VERSION ""

NS_ :

BS_:

BU_: ECU

BO_ 2550136832 M0: 8 ECU
 SG_ S0_0 : 58|2@1- (1,0) [0|0] "u0" ECU

BO_ 257 M1: 8 ECU
 SG_ S1_0 : 3|40@1- (1,0) [0|0] "u0" ECU

BO_ 258 M2: 2 ECU
 SG_ S2_0 : 15|2@0+ (1,0) [0|0] "u0" ECU

BO_ 259 M3: 2 ECU
 SG_ S3_0 : 1|10@1+ (0.125,100.5) [0|0] "u0" ECU

BO_ 260 M4: 64 ECU
 SG_ S4_0 : 0|4@1+ (10,-40) [0|0] "u0" ECU

BO_ 2550136837 M5: 8 ECU
 SG_ S5_0 : 27|19@1- (0.01,-0.25) [0|0] "u0" ECU

BO_ 262 M6: 1 ECU
 SG_ S6_0 : 3|3@1+ (1,0) [0|0] "u0" ECU

BO_ 263 M7: 8 ECU
 SG_ S7_0 : 22|1@0+ (10,-40) [0|0] "u0" ECU

BO_ 264 M8: 4 ECU
 SG_ S8_0 : 19|7@0- (10,-0.25) [0|0] "u0" ECU

BO_ 265 M9: 1 ECU
 SG_ S9_0 : 6|7@0- (0.01,100.5) [0|0] "u0" ECU

BO_ 2550136842 M10: 4 ECU
 SG_ S10_0 : 7|32@0+ (1,0) [0|0] "u0" ECU

BO_ 267 M11: 8 ECU
 SG_ S11_0 : 7|64@0- (10,-40) [0|0] "u0" ECU

BO_ 268 M12: 2 ECU
 SG_ S12_0 : 0|16@1+ (1,0) [0|0] "u0" ECU

BO_ 269 M13: 8 ECU
 SG_ S13_0 : 29|26@1+ (0.01,-0.25) [0|0] "u0" ECU

BO_ 270 M14: 2 ECU
 SG_ S14_0 : 4|4@1+ (0.001,-0.25) [0|0] "u0" ECU

BO_ 2550136847 M15: 2 ECU
 SG_ S15_0 : 5|9@1+ (0.001,0) [0|0] "u0" ECU

BO_ 272 M16: 8 ECU
 SG_ S16_0 : 51|4@0+ (0.001,100.5) [0|0] "u0" ECU

BO_ 273 M17: 8 ECU
 SG_ S17_0 : 16|33@1+ (2,-40) [0|0] "u0" ECU

BO_ 274 M18: 8 ECU
 SG_ S18_0 : 6|43@1+ (2,-40) [0|0] "u0" ECU

BO_ 275 M19: 4 ECU
 SG_ S19_0 : 7|32@0+ (1,0) [0|0] "u0" ECU

BO_ 2550136852 M20: 4 ECU
 SG_ S20_0 : 8|24@1- (1,0) [0|0] "u0" ECU

BO_ 277 M21: 4 ECU
 SG_ S21_0 : 5|3@0- (0.001,0) [0|0] "u0" ECU

BO_ 278 M22: 16 ECU
 SG_ S22_0 : 73|47@0- (2,-40) [0|0] "u0" ECU

BO_ 279 M23: 4 ECU
 SG_ S23_0 : 0|1@1- (1,0) [0|0] "u0" ECU

BO_ 280 M24: 8 ECU
 SG_ S24_0 : 3|44@0- (0.125,100.5) [0|0] "u0" ECU

BO_ 2550136857 M25: 8 ECU
 SG_ S25_0 : 9|48@0- (2,-0.25) [0|0] "u0" ECU

BO_ 282 M26: 1 ECU
 SG_ S26_0 : 2|2@1+ (1,0) [0|0] "u0" ECU

BO_ 283 M27: 8 ECU
 SG_ S27_0 : 20|12@0- (1,0) [0|0] "u0" ECU

BO_ 284 M28: 2 ECU
 SG_ S28_0 : 4|10@1+ (10,-40) [0|0] "u0" ECU

BO_ 285 M29: 2 ECU
 SG_ S29_0 : 5|1@0- (1,0) [0|0] "u0" ECU

BO_ 2550136862 M30: 8 ECU
 SG_ S30_0 : 19|21@0+ (0.001,-40) [0|0] "u0" ECU

BO_ 287 M31: 8 ECU
 SG_ S31_0 : 7|62@0+ (0.001,-0.25) [0|0] "u0" ECU

BO_ 288 M32: 4 ECU
 SG_ S32_0 : 7|32@0+ (1,0) [0|0] "u0" ECU

BO_ 289 M33: 1 ECU
 SG_ S33_0 : 7|6@0+ (0.01,100.5) [0|0] "u0" ECU

BO_ 290 M34: 8 ECU
 SG_ S34_0 : 8|22@0+ (1,0) [0|0] "u0" ECU

BO_ 2550136867 M35: 16 ECU
 SG_ S35_0 : 42|46@0+ (0.125,-40) [0|0] "u0" ECU

BO_ 292 M36: 8 ECU
 SG_ S36_0 : 4|54@1- (1,0) [0|0] "u0" ECU

BO_ 293 M37: 8 ECU
 SG_ S37_0 : 6|62@0- (0.125,-40) [0|0] "u0" ECU

BO_ 294 M38: 64 ECU
 SG_ S38_0 : 293|7@0- (0.001,100.5) [0|0] "u0" ECU

BO_ 295 M39: 8 ECU
 SG_ S39_0 : 9|18@0+ (1,0) [0|0] "u0" ECU

BO_ 2550136872 M40: 1 ECU
 SG_ S40_0 : 7|8@0- (1,0) [0|0] "u0" ECU

BO_ 297 M41: 4 ECU
 SG_ S41_0 : 5|11@0+ (1,0) [0|0] "u0" ECU

BO_ 298 M42: 8 ECU
 SG_ S42_0 : 1|6@0+ (1,0) [0|0] "u0" ECU

BO_ 299 M43: 8 ECU
 SG_ S43_0 : 0|36@1- (1,0) [0|0] "u0" ECU

BO_ 300 M44: 8 ECU
 SG_ S44_0 : 26|36@1- (10,100.5) [0|0] "u0" ECU

BO_ 2550136877 M45: 8 ECU
 SG_ S45_0 : 5|48@1+ (1,0) [0|0] "u0" ECU

BO_ 302 M46: 16 ECU
 SG_ S46_0 : 68|27@1+ (1,0) [0|0] "u0" ECU

BO_ 303 M47: 64 ECU
 SG_ S47_0 : 199|39@1- (2,-0.25) [0|0] "u0" ECU

BO_ 304 M48: 16 ECU
 SG_ S48_0 : 10|44@0+ (1,0) [0|0] "u0" ECU

BO_ 305 M49: 8 ECU
 SG_ S49_0 : 0|25@1+ (0.01,0) [0|0] "u0" ECU

BO_ 2550136882 M50: 2 ECU
 SG_ S50_0 : 3|12@1- (1,0) [0|0] "u0" ECU

BO_ 307 M51: 8 ECU
 SG_ S51_0 : 1|6@1- (10,0) [0|0] "u0" ECU

BO_ 308 M52: 1 ECU
 SG_ S52_0 : 7|4@0+ (0.01,100.5) [0|0] "u0" ECU

BO_ 309 M53: 8 ECU
 SG_ S53_0 : 6|57@0+ (0.01,-0.25) [0|0] "u0" ECU

BO_ 310 M54: 2 ECU
 SG_ S54_0 : 0|1@1+ (0.001,100.5) [0|0] "u0" ECU

BO_ 2550136887 M55: 8 ECU
 SG_ S55_0 : 17|32@1+ (1,0) [0|0] "u0" ECU

BO_ 312 M56: 8 ECU
 SG_ S56_0 : 7|64@0+ (1,0) [0|0] "u0" ECU

BO_ 313 M57: 64 ECU
 SG_ S57_0 : 289|48@0+ (1,0) [0|0] "u0" ECU

BO_ 314 M58: 1 ECU
 SG_ S58_0 : 6|6@0+ (2,-0.25) [0|0] "u0" ECU

BO_ 315 M59: 1 ECU
 SG_ S59_0 : 2|1@1+ (1,0) [0|0] "u0" ECU

BO_ 2550136892 M60: 1 ECU
 SG_ S60_0 : 7|6@0- (1,0) [0|0] "u0" ECU

BO_ 317 M61: 64 ECU
 SG_ S61_0 : 373|42@0+ (2,100.5) [0|0] "u0" ECU

BO_ 318 M62: 1 ECU
 SG_ S62_0 : 0|2@1- (1,0) [0|0] "u0" ECU

BO_ 319 M63: 1 ECU
 SG_ S63_0 : 7|8@0+ (1,0) [0|0] "u0" ECU

BO_ 320 M64: 8 ECU
 SG_ S64_0 : 1|26@0- (2,-0.25) [0|0] "u0" ECU

BO_ 2550136897 M65: 8 ECU
 SG_ S65_0 : 12|5@1- (1,0) [0|0] "u0" ECU

BO_ 322 M66: 16 ECU
 SG_ S66_0 : 96|19@1+ (1,0) [0|0] "u0" ECU

BO_ 323 M67: 4 ECU
 SG_ S67_0 : 1|24@0- (1,0) [0|0] "u0" ECU

BO_ 324 M68: 2 ECU
 SG_ S68_0 : 5|2@0- (0.125,-0.25) [0|0] "u0" ECU

BO_ 325 M69: 64 ECU
 SG_ S69_0 : 277|25@1+ (1,0) [0|0] "u0" ECU

BO_ 2550136902 M70: 8 ECU
 SG_ S70_0 : 17|37@1- (1,0) [0|0] "u0" ECU

BO_ 327 M71: 8 ECU
 SG_ S71_0 : 4|40@0+ (2,-0.25) [0|0] "u0" ECU

BO_ 328 M72: 16 ECU
 SG_ S72_0 : 111|10@1+ (0.001,0) [0|0] "u0" ECU

BO_ 329 M73: 8 ECU
 SG_ S73_0 : 39|32@0+ (1,0) [0|0] "u0" ECU

BO_ 330 M74: 1 ECU
 SG_ S74_0 : 3|3@1+ (1,0) [0|0] "u0" ECU

BO_ 2550136907 M75: 8 ECU
 SG_ S75_0 : 15|32@0+ (1,0) [0|0] "u0" ECU

BO_ 332 M76: 8 ECU
 SG_ S76_0 : 9|50@0- (0.001,0) [0|0] "u0" ECU

BO_ 333 M77: 8 ECU
 SG_ S77_0 : 5|56@0+ (1,0) [0|0] "u0" ECU

BO_ 334 M78: 16 ECU
 SG_ S78_0 : 19|64@0+ (0.5,0) [0|0] "u0" ECU

BO_ 335 M79: 2 ECU
 SG_ S79_0 : 1|13@1- (0.125,-0.25) [0|0] "u0" ECU

BO_ 2550136912 M80: 16 ECU
 SG_ S80_0 : 31|58@1- (2,-40) [0|0] "u0" ECU

BO_ 337 M81: 4 ECU
 SG_ S81_0 : 31|1@1+ (0.01,0) [0|0] "u0" ECU

BO_ 338 M82: 16 ECU
 SG_ S82_0 : 34|40@0- (0.5,-0.25) [0|0] "u0" ECU

BO_ 339 M83: 1 ECU
 SG_ S83_0 : 0|3@1+ (0.001,0) [0|0] "u0" ECU

BO_ 340 M84: 1 ECU
 SG_ S84_0 : 7|8@0+ (1,0) [0|0] "u0" ECU

BO_ 2550136917 M85: 2 ECU
 SG_ S85_0 : 2|12@1- (0.01,-40) [0|0] "u0" ECU

BO_ 342 M86: 2 ECU
 SG_ S86_0 : 4|8@1+ (1,0) [0|0] "u0" ECU

BO_ 343 M87: 4 ECU
 SG_ S87_0 : 23|14@0- (1,0) [0|0] "u0" ECU

BO_ 344 M88: 8 ECU
 SG_ S88_0 : 3|51@0+ (1,0) [0|0] "u0" ECU

BO_ 345 M89: 64 ECU
 SG_ S89_0 : 290|39@0- (0.01,0) [0|0] "u0" ECU

BO_ 2550136922 M90: 1 ECU
 SG_ S90_0 : 1|5@1- (2,-0.25) [0|0] "u0" ECU

BO_ 347 M91: 16 ECU
 SG_ S91_0 : 26|64@0+ (1,0) [0|0] "u0" ECU

BO_ 348 M92: 4 ECU
 SG_ S92_0 : 7|24@0+ (0.125,100.5) [0|0] "u0" ECU

BO_ 349 M93: 8 ECU
 SG_ S93_0 : 13|39@0+ (0.125,-0.25) [0|0] "u0" ECU

BO_ 350 M94: 64 ECU
 SG_ S94_0 : 0|32@0+ (1,0) [0|0] "u0" ECU

BO_ 2550136927 M95: 8 ECU
 SG_ S95_0 : 5|52@1+ (0.125,-40) [0|0] "u0" ECU

BO_ 352 M96: 8 ECU
 SG_ S96_0 : 3|47@1- (10,-0.25) [0|0] "u0" ECU

BO_ 353 M97: 8 ECU
 SG_ S97_0 : 7|64@0+ (0.125,-0.25) [0|0] "u0" ECU

BO_ 354 M98: 4 ECU
 SG_ S98_0 : 5|22@0- (1,0) [0|0] "u0" ECU

BO_ 355 M99: 16 ECU
 SG_ S99_0 : 55|13@1+ (1,0) [0|0] "u0" ECU

BO_ 2550136932 M100: 8 ECU
 SG_ S100_0 : 7|59@0+ (10,100.5) [0|0] "u0" ECU

BO_ 357 M101: 8 ECU
 SG_ S101_0 : 23|32@0+ (1,0) [0|0] "u0" ECU

BO_ 358 M102: 2 ECU
 SG_ S102_0 : 5|10@1- (0.125,-0.25) [0|0] "u0" ECU

BO_ 359 M103: 8 ECU
 SG_ S103_0 : 11|11@1- (2,-0.25) [0|0] "u0" ECU

BO_ 360 M104: 8 ECU
 SG_ S104_0 : 18|41@1- (2,-40) [0|0] "u0" ECU

BO_ 2550136937 M105: 8 ECU
 SG_ S105_0 : 19|11@1- (10,-40) [0|0] "u0" ECU

BO_ 362 M106: 4 ECU
 SG_ S106_0 : 22|5@0- (10,-40) [0|0] "u0" ECU

BO_ 363 M107: 16 ECU
 SG_ S107_0 : 32|35@1- (1,0) [0|0] "u0" ECU

BO_ 364 M108: 16 ECU
 SG_ S108_0 : 69|55@0+ (10,-40) [0|0] "u0" ECU

BO_ 365 M109: 64 ECU
 SG_ S109_0 : 320|12@1- (0.125,-0.25) [0|0] "u0" ECU

BO_ 2550136942 M110: 8 ECU
 SG_ S110_0 : 45|6@1+ (0.5,-40) [0|0] "u0" ECU

BO_ 367 M111: 64 ECU
 SG_ S111_0 : 165|15@1- (10,-40) [0|0] "u0" ECU

BO_ 368 M112: 8 ECU
 SG_ S112_0 : 3|51@1- (1,0) [0|0] "u0" ECU

BO_ 369 M113: 8 ECU
 SG_ S113_0 : 3|60@0+ (1,0) [0|0] "u0" ECU

BO_ 370 M114: 8 ECU
 SG_ S114_0 : 5|30@1+ (0.125,100.5) [0|0] "u0" ECU

BO_ 2550136947 M115: 1 ECU
 SG_ S115_0 : 1|1@1- (0.01,-40) [0|0] "u0" ECU

BO_ 372 M116: 2 ECU
 SG_ S116_0 : 12|2@1- (0.125,100.5) [0|0] "u0" ECU

BO_ 374 M118: 8 ECU
 SG_ S118_0 : 50|9@1+ (0.001,-0.25) [0|0] "u0" ECU

BO_ 375 M119: 8 ECU
 SG_ S119_0 : 28|32@1+ (1,0) [0|0] "u0" ECU

BO_ 2550136952 M120: 4 ECU
 SG_ S120_0 : 0|31@1+ (1,0) [0|0] "u0" ECU

BO_ 377 M121: 8 ECU
 SG_ S121_0 : 4|15@0+ (10,-40) [0|0] "u0" ECU

BO_ 378 M122: 4 ECU
 SG_ S122_0 : 6|24@0- (0.01,-0.25) [0|0] "u0" ECU

BO_ 379 M123: 2 ECU
 SG_ S123_0 : 14|2@0+ (1,0) [0|0] "u0" ECU

BO_ 380 M124: 4 ECU
 SG_ S124_0 : 4|28@1+ (1,0) [0|0] "u0" ECU

BO_ 2550136957 M125: 2 ECU
 SG_ S125_0 : 6|11@0+ (2,0) [0|0] "u0" ECU

BO_ 382 M126: 1 ECU
 SG_ S126_0 : 4|5@0+ (1,0) [0|0] "u0" ECU

BO_ 383 M127: 64 ECU
 SG_ S127_0 : 219|64@0+ (1,0) [0|0] "u0" ECU

BO_ 384 M128: 16 ECU
 SG_ S128_0 : 38|32@1+ (1,0) [0|0] "u0" ECU

BO_ 385 M129: 4 ECU
 SG_ S129_0 : 18|7@1- (1,0) [0|0] "u0" ECU

BO_ 2550136962 M130: 8 ECU
 SG_ S130_0 : 9|32@1+ (1,0) [0|0] "u0" ECU

BO_ 387 M131: 16 ECU
 SG_ S131_0 : 78|55@0+ (10,-0.25) [0|0] "u0" ECU

BO_ 388 M132: 16 ECU
 SG_ S132_0 : 20|57@1- (1,0) [0|0] "u0" ECU

BO_ 389 M133: 1 ECU
 SG_ S133_0 : 7|1@1+ (2,-0.25) [0|0] "u0" ECU

BO_ 390 M134: 8 ECU
 SG_ S134_0 : 7|23@1+ (1,0) [0|0] "u0" ECU

BO_ 2550136967 M135: 16 ECU
 SG_ S135_0 : 45|40@0- (1,0) [0|0] "u0" ECU

BO_ 392 M136: 8 ECU
 SG_ S136_0 : 44|15@1+ (0.001,-0.25) [0|0] "u0" ECU

BO_ 393 M137: 64 ECU
 SG_ S137_0 : 5|52@1+ (0.001,0) [0|0] "u0" ECU

BO_ 394 M138: 64 ECU
 SG_ S138_0 : 461|15@1- (1,0) [0|0] "u0" ECU

BO_ 395 M139: 8 ECU
 SG_ S139_0 : 29|32@1- (1,0) [0|0] "u0" ECU

BO_ 2550136972 M140: 8 ECU
 SG_ S140_0 : 1|61@1- (1,0) [0|0] "u0" ECU

BO_ 397 M141: 8 ECU
 SG_ S141_0 : 5|26@1- (1,0) [0|0] "u0" ECU

BO_ 398 M142: 1 ECU
 SG_ S142_0 : 0|1@0+ (2,100.5) [0|0] "u0" ECU

BO_ 399 M143: 8 ECU
 SG_ S143_0 : 37|13@0+ (0.125,-40) [0|0] "u0" ECU

BO_ 400 M144: 8 ECU
 SG_ S144_0 : 13|16@1+ (0.001,-40) [0|0] "u0" ECU

BO_ 2550136977 M145: 4 ECU
 SG_ S145_0 : 0|26@1- (0.5,0) [0|0] "u0" ECU

BO_ 402 M146: 16 ECU
 SG_ S146_0 : 102|23@1+ (1,0) [0|0] "u0" ECU

BO_ 403 M147: 8 ECU
 SG_ S147_0 : 5|55@1- (1,0) [0|0] "u0" ECU

BO_ 404 M148: 64 ECU
 SG_ S148_0 : 479|35@0+ (1,0) [0|0] "u0" ECU

BO_ 405 M149: 16 ECU
 SG_ S149_0 : 22|38@0+ (1,0) [0|0] "u0" ECU

BO_ 2550136982 M150: 4 ECU
 SG_ S150_0 : 1|24@1- (0.125,-0.25) [0|0] "u0" ECU

BO_ 407 M151: 8 ECU
 SG_ S151_0 : 25|15@1+ (1,0) [0|0] "u0" ECU

BO_ 408 M152: 1 ECU
 SG_ S152_0 : 4|2@0+ (1,0) [0|0] "u0" ECU

BO_ 409 M153: 4 ECU
 SG_ S153_0 : 8|18@1+ (10,0) [0|0] "u0" ECU

BO_ 410 M154: 1 ECU
 SG_ S154_0 : 7|8@0- (0.125,-40) [0|0] "u0" ECU

BO_ 2550136987 M155: 1 ECU
 SG_ S155_0 : 1|1@0- (1,0) [0|0] "u0" ECU

BO_ 412 M156: 2 ECU
 SG_ S156_0 : 0|10@1- (1,0) [0|0] "u0" ECU

BO_ 413 M157: 1 ECU
 SG_ S157_0 : 0|7@1+ (1,0) [0|0] "u0" ECU

BO_ 414 M158: 8 ECU
 SG_ S158_0 : 12|46@1+ (1,0) [0|0] "u0" ECU

BO_ 415 M159: 2 ECU
 SG_ S159_0 : 7|3@0- (1,0) [0|0] "u0" ECU

BO_ 2550136992 M160: 64 ECU
 SG_ S160_0 : 53|51@1- (0.125,-0.25) [0|0] "u0" ECU

BO_ 417 M161: 64 ECU
 SG_ S161_0 : 294|20@1+ (0.01,-40) [0|0] "u0" ECU

BO_ 418 M162: 2 ECU
 SG_ S162_0 : 7|6@1- (1,0) [0|0] "u0" ECU

BO_ 419 M163: 8 ECU
 SG_ S163_0 : 9|49@0+ (1,0) [0|0] "u0" ECU

BO_ 420 M164: 4 ECU
 SG_ S164_0 : 19|6@1- (1,0) [0|0] "u0" ECU

BO_ 2550136997 M165: 8 ECU
 SG_ S165_0 : 5|43@0- (10,-0.25) [0|0] "u0" ECU

BO_ 422 M166: 4 ECU
 SG_ S166_0 : 0|14@1- (0.125,0) [0|0] "u0" ECU

BO_ 423 M167: 1 ECU
 SG_ S167_0 : 0|7@1- (1,0) [0|0] "u0" ECU

BO_ 424 M168: 2 ECU
 SG_ S168_0 : 4|7@0- (0.125,0) [0|0] "u0" ECU

BO_ 425 M169: 8 ECU
 SG_ S169_0 : 35|8@0- (1,0) [0|0] "u0" ECU

BO_ 2550137002 M170: 4 ECU
 SG_ S170_0 : 6|25@1+ (1,0) [0|0] "u0" ECU

BO_ 427 M171: 8 ECU
 SG_ S171_0 : 16|48@1+ (1,0) [0|0] "u0" ECU

BO_ 428 M172: 8 ECU
 SG_ S172_0 : 3|55@0+ (0.5,0) [0|0] "u0" ECU

BO_ 429 M173: 2 ECU
 SG_ S173_0 : 3|10@1+ (0.5,-0.25) [0|0] "u0" ECU

BO_ 430 M174: 8 ECU
 SG_ S174_0 : 56|8@1+ (0.001,-40) [0|0] "u0" ECU

BO_ 2550137007 M175: 64 ECU
 SG_ S175_0 : 305|9@1- (1,0) [0|0] "u0" ECU

BO_ 432 M176: 1 ECU
 SG_ S176_0 : 2|6@1+ (0.125,-40) [0|0] "u0" ECU

BO_ 433 M177: 8 ECU
 SG_ S177_0 : 7|64@0+ (1,0) [0|0] "u0" ECU

BO_ 434 M178: 8 ECU
 SG_ S178_0 : 2|61@1- (1,0) [0|0] "u0" ECU

BO_ 435 M179: 16 ECU
 SG_ S179_0 : 32|41@1+ (0.125,-40) [0|0] "u0" ECU

BO_ 2550137012 M180: 1 ECU
 SG_ S180_0 : 0|8@1+ (0.001,-0.25) [0|0] "u0" ECU

BO_ 437 M181: 8 ECU
 SG_ S181_0 : 35|24@0- (0.01,0) [0|0] "u0" ECU

BO_ 438 M182: 8 ECU
 SG_ S182_0 : 5|43@1+ (0.125,0) [0|0] "u0" ECU

BO_ 439 M183: 8 ECU
 SG_ S183_0 : 7|47@1- (0.001,-0.25) [0|0] "u0" ECU

BO_ 440 M184: 8 ECU
 SG_ S184_0 : 0|59@1- (1,0) [0|0] "u0" ECU

BO_ 2550137017 M185: 16 ECU
 SG_ S185_0 : 79|28@1+ (1,0) [0|0] "u0" ECU

BO_ 442 M186: 8 ECU
 SG_ S186_0 : 0|64@1+ (1,0) [0|0] "u0" ECU

BO_ 443 M187: 2 ECU
 SG_ S187_0 : 1|8@1+ (1,0) [0|0] "u0" ECU

BO_ 444 M188: 16 ECU
 SG_ S188_0 : 37|62@1- (1,0) [0|0] "u0" ECU

BO_ 445 M189: 1 ECU
 SG_ S189_0 : 6|1@1- (1,0) [0|0] "u0" ECU

BO_ 2550137022 M190: 8 ECU
 SG_ S190_0 : 25|33@1+ (2,-0.25) [0|0] "u0" ECU

BO_ 447 M191: 8 ECU
 SG_ S191_0 : 0|60@1- (1,0) [0|0] "u0" ECU

BO_ 448 M192: 1 ECU
 SG_ S192_0 : 2|2@1+ (1,0) [0|0] "u0" ECU

BO_ 449 M193: 2 ECU
 SG_ S193_0 : 0|8@0- (0.01,0) [0|0] "u0" ECU

BO_ 450 M194: 8 ECU
 SG_ S194_0 : 26|7@1+ (1,0) [0|0] "u0" ECU

BO_ 2550137027 M195: 16 ECU
 SG_ S195_0 : 20|19@0+ (1,0) [0|0] "u0" ECU

BO_ 452 M196: 8 ECU
 SG_ S196_0 : 41|17@1+ (1,0) [0|0] "u0" ECU

BO_ 453 M197: 1 ECU
 SG_ S197_0 : 3|4@0+ (1,0) [0|0] "u0" ECU

BO_ 454 M198: 16 ECU
 SG_ S198_0 : 75|20@1+ (1,0) [0|0] "u0" ECU

BO_ 455 M199: 1 ECU
 SG_ S199_0 : 3|2@0- (0.5,-0.25) [0|0] "u0" ECU

BO_ 2550137032 M200: 16 ECU
 SG_ S200_0 : 90|35@1- (0.125,-40) [0|0] "u0" ECU

BO_ 457 M201: 4 ECU
 SG_ S201_0 : 7|32@0+ (0.5,0) [0|0] "u0" ECU

BO_ 458 M202: 8 ECU
 SG_ S202_0 : 0|64@1+ (1,0) [0|0] "u0" ECU

BO_ 459 M203: 2 ECU
 SG_ S203_0 : 4|11@1+ (10,0) [0|0] "u0" ECU

BO_ 460 M204: 8 ECU
 SG_ S204_0 : 6|58@1+ (2,100.5) [0|0] "u0" ECU

BO_ 2550137037 M205: 16 ECU
 SG_ S205_0 : 25|43@1- (1,0) [0|0] "u0" ECU

BO_ 462 M206: 1 ECU
 SG_ S206_0 : 0|6@1+ (1,0) [0|0] "u0" ECU

BO_ 463 M207: 64 ECU
 SG_ S207_0 : 431|34@0- (1,0) [0|0] "u0" ECU

BO_ 464 M208: 8 ECU
 SG_ S208_0 : 3|9@0- (0.125,-0.25) [0|0] "u0" ECU

BO_ 465 M209: 1 ECU
 SG_ S209_0 : 4|4@1+ (2,-40) [0|0] "u0" ECU

BO_ 2550137042 M210: 2 ECU
 SG_ S210_0 : 13|2@0- (1,0) [0|0] "u0" ECU

BO_ 467 M211: 8 ECU
 SG_ S211_0 : 13|32@0+ (1,0) [0|0] "u0" ECU

BO_ 468 M212: 8 ECU
 SG_ S212_0 : 8|12@1+ (0.001,0) [0|0] "u0" ECU

BO_ 469 M213: 4 ECU
 SG_ S213_0 : 0|19@1+ (2,100.5) [0|0] "u0" ECU

BO_ 470 M214: 8 ECU
 SG_ S214_0 : 9|43@1+ (0.5,100.5) [0|0] "u0" ECU

BO_ 2550137047 M215: 16 ECU
 SG_ S215_0 : 53|17@0+ (1,0) [0|0] "u0" ECU

BO_ 473 M217: 8 ECU
 SG_ S217_0 : 34|20@0- (0.001,0) [0|0] "u0" ECU

BO_ 474 M218: 4 ECU
 SG_ S218_0 : 9|11@0- (1,0) [0|0] "u0" ECU

BO_ 475 M219: 64 ECU
 SG_ S219_0 : 241|47@0- (1,0) [0|0] "u0" ECU

BO_ 2550137052 M220: 2 ECU
 SG_ S220_0 : 7|16@0- (0.5,100.5) [0|0] "u0" ECU

BO_ 477 M221: 1 ECU
 SG_ S221_0 : 2|5@1- (0.01,100.5) [0|0] "u0" ECU

BO_ 478 M222: 2 ECU
 SG_ S222_0 : 6|3@0- (0.001,100.5) [0|0] "u0" ECU

BO_ 479 M223: 1 ECU
 SG_ S223_0 : 4|1@1+ (1,0) [0|0] "u0" ECU

BO_ 480 M224: 4 ECU
 SG_ S224_0 : 14|21@0+ (1,0) [0|0] "u0" ECU

BO_ 2550137057 M225: 1 ECU
 SG_ S225_0 : 4|2@1+ (1,0) [0|0] "u0" ECU

BO_ 482 M226: 64 ECU
 SG_ S226_0 : 84|19@0+ (0.125,0) [0|0] "u0" ECU

BO_ 483 M227: 64 ECU
 SG_ S227_0 : 286|64@1+ (1,0) [0|0] "u0" ECU

BO_ 484 M228: 64 ECU
 SG_ S228_0 : 136|13@0- (1,0) [0|0] "u0" ECU

BO_ 485 M229: 1 ECU
 SG_ S229_0 : 2|5@1+ (1,0) [0|0] "u0" ECU

BO_ 2550137062 M230: 8 ECU
 SG_ S230_0 : 12|44@0+ (1,0) [0|0] "u0" ECU

BO_ 487 M231: 1 ECU
 SG_ S231_0 : 7|1@0- (0.5,-40) [0|0] "u0" ECU

BO_ 488 M232: 4 ECU
 SG_ S232_0 : 3|28@1- (1,0) [0|0] "u0" ECU

BO_ 489 M233: 16 ECU
 SG_ S233_0 : 68|23@0- (0.5,0) [0|0] "u0" ECU

BO_ 490 M234: 8 ECU
 SG_ S234_0 : 19|16@0+ (0.01,-0.25) [0|0] "u0" ECU

BO_ 2550137067 M235: 8 ECU
 SG_ S235_0 : 5|36@0+ (0.01,-0.25) [0|0] "u0" ECU

BO_ 492 M236: 16 ECU
 SG_ S236_0 : 28|64@1+ (1,0) [0|0] "u0" ECU

BO_ 493 M237: 8 ECU
 SG_ S237_0 : 6|2@1+ (1,0) [0|0] "u0" ECU

BO_ 494 M238: 8 ECU
 SG_ S238_0 : 7|64@0+ (10,-0.25) [0|0] "u0" ECU

BO_ 495 M239: 8 ECU
 SG_ S239_0 : 7|18@0- (2,-0.25) [0|0] "u0" ECU

BO_ 2550137072 M240: 8 ECU
 SG_ S240_0 : 7|64@0+ (1,0) [0|0] "u0" ECU

BO_ 497 M241: 64 ECU
 SG_ S241_0 : 76|5@1+ (1,0) [0|0] "u0" ECU

BO_ 498 M242: 16 ECU
 SG_ S242_0 : 13|26@1+ (0.5,-0.25) [0|0] "u0" ECU

BO_ 499 M243: 8 ECU
 SG_ S243_0 : 10|37@0- (1,0) [0|0] "u0" ECU

BO_ 500 M244: 8 ECU
 SG_ S244_0 : 4|61@0- (1,0) [0|0] "u0" ECU

BO_ 2550137077 M245: 4 ECU
 SG_ S245_0 : 13|10@0+ (1,0) [0|0] "u0" ECU

BO_ 502 M246: 2 ECU
 SG_ S246_0 : 3|7@1- (0.001,-40) [0|0] "u0" ECU

BO_ 503 M247: 16 ECU
 SG_ S247_0 : 49|62@1+ (2,0) [0|0] "u0" ECU

BO_ 504 M248: 64 ECU
 SG_ S248_0 : 179|20@0- (1,0) [0|0] "u0" ECU

BO_ 505 M249: 8 ECU
 SG_ S249_0 : 19|26@1- (2,0) [0|0] "u0" ECU

BO_ 2550137082 M250: 8 ECU
 SG_ S250_0 : 22|30@0- (0.01,-40) [0|0] "u0" ECU

BO_ 507 M251: 16 ECU
 SG_ S251_0 : 16|60@0- (0.5,-0.25) [0|0] "u0" ECU

BO_ 508 M252: 8 ECU
 SG_ S252_0 : 0|54@1- (10,-0.25) [0|0] "u0" ECU

BO_ 509 M253: 8 ECU
 SG_ S253_0 : 24|2@1+ (1,0) [0|0] "u0" ECU

BO_ 510 M254: 8 ECU
 SG_ S254_0 : 8|32@1+ (1,0) [0|0] "u0" ECU

BO_ 2550137087 M255: 64 ECU
 SG_ S255_0 : 281|18@1- (0.01,100.5) [0|0] "u0" ECU

BO_ 512 M256: 16 ECU
 SG_ S256_0 : 56|9@1- (1,0) [0|0] "u0" ECU

BO_ 513 M257: 16 ECU
 SG_ S257_0 : 48|58@1- (1,0) [0|0] "u0" ECU

BO_ 514 M258: 2 ECU
 SG_ S258_0 : 5|13@0- (10,0) [0|0] "u0" ECU

BO_ 515 M259: 8 ECU
 SG_ S259_0 : 14|10@1- (1,0) [0|0] "u0" ECU

BO_ 2550137092 M260: 4 ECU
 SG_ S260_0 : 1|26@1+ (1,0) [0|0] "u0" ECU

BO_ 517 M261: 8 ECU
 SG_ S261_0 : 5|55@0+ (1,0) [0|0] "u0" ECU

BO_ 518 M262: 4 ECU
 SG_ S262_0 : 11|18@0+ (1,0) [0|0] "u0" ECU

BO_ 519 M263: 4 ECU
 SG_ S263_0 : 7|32@0+ (1,0) [0|0] "u0" ECU

BO_ 520 M264: 4 ECU
 SG_ S264_0 : 7|25@0- (1,0) [0|0] "u0" ECU

BO_ 2550137097 M265: 2 ECU
 SG_ S265_0 : 1|7@1+ (0.5,100.5) [0|0] "u0" ECU

BO_ 522 M266: 2 ECU
 SG_ S266_0 : 0|5@1+ (0.001,100.5) [0|0] "u0" ECU

BO_ 523 M267: 4 ECU
 SG_ S267_0 : 1|4@0- (1,0) [0|0] "u0" ECU

BO_ 524 M268: 8 ECU
 SG_ S268_0 : 14|41@1- (2,-0.25) [0|0] "u0" ECU

BO_ 525 M269: 8 ECU
 SG_ S269_0 : 35|17@0+ (0.5,-0.25) [0|0] "u0" ECU

BO_ 2550137102 M270: 16 ECU
 SG_ S270_0 : 59|54@1+ (0.5,-40) [0|0] "u0" ECU

BO_ 527 M271: 1 ECU
 SG_ S271_0 : 4|1@0- (1,0) [0|0] "u0" ECU

BO_ 528 M272: 8 ECU
 SG_ S272_0 : 0|56@0+ (1,0) [0|0] "u0" ECU

BO_ 529 M273: 16 ECU
 SG_ S273_0 : 103|26@0- (0.01,-40) [0|0] "u0" ECU

BO_ 530 M274: 2 ECU
 SG_ S274_0 : 0|2@1- (1,0) [0|0] "u0" ECU

BO_ 2550137107 M275: 2 ECU
 SG_ S275_0 : 2|5@1+ (1,0) [0|0] "u0" ECU

BO_ 532 M276: 4 ECU
 SG_ S276_0 : 7|32@0+ (10,-0.25) [0|0] "u0" ECU

BO_ 533 M277: 2 ECU
 SG_ S277_0 : 0|14@1- (2,100.5) [0|0] "u0" ECU

BO_ 534 M278: 64 ECU
 SG_ S278_0 : 346|39@1- (1,0) [0|0] "u0" ECU

BO_ 535 M279: 16 ECU
 SG_ S279_0 : 68|57@0+ (0.5,0) [0|0] "u0" ECU

BO_ 2550137112 M280: 8 ECU
 SG_ S280_0 : 4|7@0- (1,0) [0|0] "u0" ECU

BO_ 537 M281: 8 ECU
 SG_ S281_0 : 26|19@0- (0.001,-0.25) [0|0] "u0" ECU

BO_ 538 M282: 16 ECU
 SG_ S282_0 : 22|19@0+ (1,0) [0|0] "u0" ECU

BO_ 539 M283: 8 ECU
 SG_ S283_0 : 14|36@1+ (0.5,-40) [0|0] "u0" ECU

BO_ 540 M284: 16 ECU
 SG_ S284_0 : 22|54@0- (0.125,100.5) [0|0] "u0" ECU

BO_ 2550137117 M285: 4 ECU
 SG_ S285_0 : 0|18@0+ (0.125,100.5) [0|0] "u0" ECU

BO_ 542 M286: 16 ECU
 SG_ S286_0 : 56|55@1- (2,-40) [0|0] "u0" ECU

BO_ 543 M287: 8 ECU
 SG_ S287_0 : 37|16@0- (0.001,-0.25) [0|0] "u0" ECU

BO_ 544 M288: 8 ECU
 SG_ S288_0 : 27|23@1+ (0.001,-40) [0|0] "u0" ECU

BO_ 545 M289: 8 ECU
 SG_ S289_0 : 35|21@1+ (0.01,-40) [0|0] "u0" ECU

BO_ 2550137122 M290: 8 ECU
 SG_ S290_0 : 7|64@0+ (1,0) [0|0] "u0" ECU

BO_ 547 M291: 8 ECU
 SG_ S291_0 : 21|27@1+ (1,0) [0|0] "u0" ECU

BO_ 548 M292: 8 ECU
 SG_ S292_0 : 30|32@1+ (1,0) [0|0] "u0" ECU

BO_ 549 M293: 4 ECU
 SG_ S293_0 : 1|30@1+ (0.01,-0.25) [0|0] "u0" ECU

BO_ 550 M294: 16 ECU
 SG_ S294_0 : 57|20@0- (0.5,100.5) [0|0] "u0" ECU

BO_ 2550137127 M295: 64 ECU
 SG_ S295_0 : 403|20@0+ (0.01,0) [0|0] "u0" ECU

BO_ 552 M296: 16 ECU
 SG_ S296_0 : 111|8@1+ (0.001,100.5) [0|0] "u0" ECU

BO_ 553 M297: 2 ECU
 SG_ S297_0 : 0|3@0- (1,0) [0|0] "u0" ECU

BO_ 554 M298: 16 ECU
 SG_ S298_0 : 32|17@1- (1,0) [0|0] "u0" ECU

BO_ 555 M299: 4 ECU
 SG_ S299_0 : 29|4@0- (0.5,-40) [0|0] "u0" ECU

BO_ 2550137132 M300: 2 ECU
 SG_ S300_0 : 0|13@1- (0.125,-40) [0|0] "u0" ECU

BO_ 557 M301: 8 ECU
 SG_ S301_0 : 46|9@1+ (0.001,100.5) [0|0] "u0" ECU

BO_ 558 M302: 8 ECU
 SG_ S302_0 : 2|44@1- (1,0) [0|0] "u0" ECU

BO_ 559 M303: 1 ECU
 SG_ S303_0 : 6|5@0+ (2,0) [0|0] "u0" ECU

BO_ 560 M304: 4 ECU
 SG_ S304_0 : 2|9@1- (1,0) [0|0] "u0" ECU

BO_ 2550137137 M305: 4 ECU
 SG_ S305_0 : 7|32@0+ (1,0) [0|0] "u0" ECU

BO_ 562 M306: 1 ECU
 SG_ S306_0 : 5|5@0+ (10,-0.25) [0|0] "u0" ECU

BO_ 563 M307: 1 ECU
 SG_ S307_0 : 1|5@1+ (10,0) [0|0] "u0" ECU

BO_ 564 M308: 1 ECU
 SG_ S308_0 : 6|6@0+ (1,0) [0|0] "u0" ECU

BO_ 565 M309: 8 ECU
 SG_ S309_0 : 44|16@0+ (2,-0.25) [0|0] "u0" ECU

BO_ 2550137142 M310: 2 ECU
 SG_ S310_0 : 7|13@0+ (2,100.5) [0|0] "u0" ECU

BO_ 567 M311: 1 ECU
 SG_ S311_0 : 6|2@1- (2,0) [0|0] "u0" ECU

BO_ 568 M312: 8 ECU
 SG_ S312_0 : 7|57@1- (0.01,-40) [0|0] "u0" ECU

BO_ 569 M313: 16 ECU
 SG_ S313_0 : 67|28@0+ (1,0) [0|0] "u0" ECU

BO_ 570 M314: 8 ECU
 SG_ S314_0 : 5|49@0+ (1,0) [0|0] "u0" ECU

BO_ 2550137147 M315: 8 ECU
 SG_ S315_0 : 9|46@0+ (0.125,-0.25) [0|0] "u0" ECU

BO_ 572 M316: 8 ECU
 SG_ S316_0 : 1|15@1- (1,0) [0|0] "u0" ECU

BO_ 573 M317: 16 ECU
 SG_ S317_0 : 34|26@1- (1,0) [0|0] "u0" ECU

BO_ 574 M318: 8 ECU
 SG_ S318_0 : 6|24@0- (1,0) [0|0] "u0" ECU

BO_ 575 M319: 8 ECU
 SG_ S319_0 : 14|55@0- (1,0) [0|0] "u0" ECU

BO_ 2550137152 M320: 8 ECU
 SG_ S320_0 : 0|26@0- (1,0) [0|0] "u0" ECU

BO_ 577 M321: 1 ECU
 SG_ S321_0 : 7|5@0+ (1,0) [0|0] "u0" ECU

BO_ 578 M322: 2 ECU
 SG_ S322_0 : 6|15@0- (1,0) [0|0] "u0" ECU

BO_ 579 M323: 1 ECU
 SG_ S323_0 : 5|4@0- (1,0) [0|0] "u0" ECU

BO_ 580 M324: 8 ECU
 SG_ S324_0 : 7|48@0- (0.001,-0.25) [0|0] "u0" ECU

BO_ 2550137157 M325: 4 ECU
 SG_ S325_0 : 0|3@1+ (1,0) [0|0] "u0" ECU

BO_ 582 M326: 64 ECU
 SG_ S326_0 : 308|8@0- (1,0) [0|0] "u0" ECU

BO_ 583 M327: 8 ECU
 SG_ S327_0 : 7|61@0+ (0.125,100.5) [0|0] "u0" ECU

BO_ 584 M328: 8 ECU
 SG_ S328_0 : 19|44@1- (2,0) [0|0] "u0" ECU

BO_ 585 M329: 64 ECU
 SG_ S329_0 : 110|30@1+ (0.01,-0.25) [0|0] "u0" ECU

BO_ 2550137162 M330: 64 ECU
 SG_ S330_0 : 331|51@1+ (0.5,100.5) [0|0] "u0" ECU

BO_ 587 M331: 8 ECU
 SG_ S331_0 : 4|58@0- (1,0) [0|0] "u0" ECU

BO_ 588 M332: 8 ECU
 SG_ S332_0 : 2|22@1+ (10,-40) [0|0] "u0" ECU

BO_ 589 M333: 4 ECU
 SG_ S333_0 : 2|6@1+ (0.5,-40) [0|0] "u0" ECU

BO_ 590 M334: 64 ECU
 SG_ S334_0 : 148|17@1- (0.001,-0.25) [0|0] "u0" ECU

BO_ 2550137167 M335: 4 ECU
 SG_ S335_0 : 2|28@1+ (10,-40) [0|0] "u0" ECU

BO_ 592 M336: 4 ECU
 SG_ S336_0 : 5|29@0- (1,0) [0|0] "u0" ECU

BO_ 593 M337: 16 ECU
 SG_ S337_0 : 66|52@0- (10,-40) [0|0] "u0" ECU

BO_ 594 M338: 16 ECU
 SG_ S338_0 : 37|29@1+ (1,0) [0|0] "u0" ECU

BO_ 595 M339: 8 ECU
 SG_ S339_0 : 18|36@0+ (0.5,-0.25) [0|0] "u0" ECU

BO_ 2550137172 M340: 8 ECU
 SG_ S340_0 : 11|49@1- (1,0) [0|0] "u0" ECU

BO_ 597 M341: 8 ECU
 SG_ S341_0 : 25|27@1+ (0.5,0) [0|0] "u0" ECU

BO_ 598 M342: 8 ECU
 SG_ S342_0 : 0|52@1+ (1,0) [0|0] "u0" ECU

BO_ 599 M343: 64 ECU
 SG_ S343_0 : 473|18@0- (0.01,100.5) [0|0] "u0" ECU

BO_ 600 M344: 1 ECU
 SG_ S344_0 : 1|5@1+ (0.001,100.5) [0|0] "u0" ECU

BO_ 2550137177 M345: 8 ECU
 SG_ S345_0 : 31|8@0+ (1,0) [0|0] "u0" ECU

BO_ 602 M346: 64 ECU
 SG_ S346_0 : 246|64@0- (0.5,100.5) [0|0] "u0" ECU

BO_ 603 M347: 4 ECU
 SG_ S347_0 : 18|10@1- (1,0) [0|0] "u0" ECU

BO_ 604 M348: 8 ECU
 SG_ S348_0 : 7|39@1+ (0.001,100.5) [0|0] "u0" ECU

BO_ 605 M349: 8 ECU
 SG_ S349_0 : 26|29@0+ (1,0) [0|0] "u0" ECU

BO_ 2550137182 M350: 4 ECU
 SG_ S350_0 : 13|8@1- (0.125,-0.25) [0|0] "u0" ECU

BO_ 607 M351: 8 ECU
 SG_ S351_0 : 12|18@1+ (1,0) [0|0] "u0" ECU

BO_ 608 M352: 2 ECU
 SG_ S352_0 : 7|16@0- (1,0) [0|0] "u0" ECU

BO_ 609 M353: 64 ECU
 SG_ S353_0 : 242|29@1+ (1,0) [0|0] "u0" ECU

BO_ 610 M354: 64 ECU
 SG_ S354_0 : 119|43@0+ (0.001,0) [0|0] "u0" ECU

BO_ 2550137187 M355: 8 ECU
 SG_ S355_0 : 27|27@1- (0.01,-0.25) [0|0] "u0" ECU

BO_ 612 M356: 16 ECU
 SG_ S356_0 : 40|64@0+ (0.125,100.5) [0|0] "u0" ECU

BO_ 613 M357: 1 ECU
 SG_ S357_0 : 6|1@0- (1,0) [0|0] "u0" ECU

BO_ 614 M358: 8 ECU
 SG_ S358_0 : 38|12@1+ (1,0) [0|0] "u0" ECU

BO_ 615 M359: 64 ECU
 SG_ S359_0 : 243|8@1+ (0.5,100.5) [0|0] "u0" ECU

BO_ 2550137192 M360: 1 ECU
 SG_ S360_0 : 5|3@1- (0.125,0) [0|0] "u0" ECU

BO_ 617 M361: 1 ECU
 SG_ S361_0 : 4|4@1+ (0.5,0) [0|0] "u0" ECU

BO_ 618 M362: 8 ECU
 SG_ S362_0 : 7|64@0- (1,0) [0|0] "u0" ECU

BO_ 619 M363: 16 ECU
 SG_ S363_0 : 6|5@0- (1,0) [0|0] "u0" ECU

BO_ 620 M364: 16 ECU
 SG_ S364_0 : 12|23@0+ (0.01,0) [0|0] "u0" ECU

BO_ 2550137197 M365: 8 ECU
 SG_ S365_0 : 2|39@1- (10,-40) [0|0] "u0" ECU

BO_ 622 M366: 64 ECU
 SG_ S366_0 : 336|5@1+ (10,-40) [0|0] "u0" ECU

BO_ 623 M367: 8 ECU
 SG_ S367_0 : 9|4@0+ (2,-0.25) [0|0] "u0" ECU

BO_ 624 M368: 64 ECU
 SG_ S368_0 : 194|28@0+ (1,0) [0|0] "u0" ECU

BO_ 625 M369: 4 ECU
 SG_ S369_0 : 17|3@0+ (1,0) [0|0] "u0" ECU

BO_ 2550137202 M370: 1 ECU
 SG_ S370_0 : 6|1@1+ (0.5,0) [0|0] "u0" ECU

BO_ 627 M371: 1 ECU
 SG_ S371_0 : 0|3@1+ (1,0) [0|0] "u0" ECU

BO_ 628 M372: 8 ECU
 SG_ S372_0 : 21|40@0- (10,-40) [0|0] "u0" ECU

BO_ 629 M373: 16 ECU
 SG_ S373_0 : 47|29@1+ (0.01,-40) [0|0] "u0" ECU

BO_ 630 M374: 8 ECU
 SG_ S374_0 : 1|36@1- (0.001,100.5) [0|0] "u0" ECU

BO_ 2550137207 M375: 16 ECU
 SG_ S375_0 : 79|48@0- (2,100.5) [0|0] "u0" ECU

BO_ 632 M376: 1 ECU
 SG_ S376_0 : 0|5@1+ (0.5,100.5) [0|0] "u0" ECU

BO_ 633 M377: 8 ECU
 SG_ S377_0 : 14|21@0- (0.001,0) [0|0] "u0" ECU

BO_ 634 M378: 8 ECU
 SG_ S378_0 : 2|19@0- (0.5,-0.25) [0|0] "u0" ECU

BO_ 635 M379: 8 ECU
 SG_ S379_0 : 16|32@0+ (1,0) [0|0] "u0" ECU

BO_ 2550137212 M380: 2 ECU
 SG_ S380_0 : 0|9@0+ (1,0) [0|0] "u0" ECU

BO_ 637 M381: 64 ECU
 SG_ S381_0 : 390|32@0- (1,0) [0|0] "u0" ECU

BO_ 638 M382: 64 ECU
 SG_ S382_0 : 23|16@0- (1,0) [0|0] "u0" ECU

BO_ 639 M383: 64 ECU
 SG_ S383_0 : 335|62@1- (1,0) [0|0] "u0" ECU

BO_ 640 M384: 2 ECU
 SG_ S384_0 : 4|10@1+ (0.001,-40) [0|0] "u0" ECU

BO_ 2550137217 M385: 8 ECU
 SG_ S385_0 : 9|43@1- (1,0) [0|0] "u0" ECU

BO_ 642 M386: 8 ECU
 SG_ S386_0 : 23|19@0- (1,0) [0|0] "u0" ECU

BO_ 643 M387: 8 ECU
 SG_ S387_0 : 13|50@1- (10,-0.25) [0|0] "u0" ECU

BO_ 644 M388: 2 ECU
 SG_ S388_0 : 5|4@0+ (0.001,100.5) [0|0] "u0" ECU

BO_ 645 M389: 8 ECU
 SG_ S389_0 : 50|12@1- (10,-40) [0|0] "u0" ECU

BO_ 2550137222 M390: 8 ECU
 SG_ S390_0 : 10|32@1+ (1,0) [0|0] "u0" ECU

BO_ 647 M391: 4 ECU
 SG_ S391_0 : 19|11@1+ (0.125,0) [0|0] "u0" ECU

BO_ 648 M392: 8 ECU
 SG_ S392_0 : 34|20@1+ (1,0) [0|0] "u0" ECU

BO_ 649 M393: 64 ECU
 SG_ S393_0 : 141|58@0+ (1,0) [0|0] "u0" ECU

BO_ 650 M394: 1 ECU
 SG_ S394_0 : 2|3@0- (0.5,-0.25) [0|0] "u0" ECU

BO_ 2550137227 M395: 8 ECU
 SG_ S395_0 : 8|13@0- (0.125,-40) [0|0] "u0" ECU

BO_ 652 M396: 8 ECU
 SG_ S396_0 : 7|64@0+ (1,0) [0|0] "u0" ECU

BO_ 653 M397: 64 ECU
 SG_ S397_0 : 419|54@0- (0.125,100.5) [0|0] "u0" ECU

BO_ 654 M398: 8 ECU
 SG_ S398_0 : 4|36@1- (1,0) [0|0] "u0" ECU

BO_ 655 M399: 2 ECU
 SG_ S399_0 : 13|6@0- (0.001,-0.25) [0|0] "u0" ECU

BO_ 2550137232 M400: 4 ECU
 SG_ S400_0 : 4|15@0- (1,0) [0|0] "u0" ECU

BO_ 657 M401: 64 ECU
 SG_ S401_0 : 17|44@0- (1,0) [0|0] "u0" ECU

BO_ 658 M402: 16 ECU
 SG_ S402_0 : 43|13@1- (1,0) [0|0] "u0" ECU

BO_ 659 M403: 8 ECU
 SG_ S403_0 : 5|43@1- (0.125,-40) [0|0] "u0" ECU

BO_ 660 M404: 16 ECU
 SG_ S404_0 : 37|38@1- (1,0) [0|0] "u0" ECU

BO_ 2550137237 M405: 64 ECU
 SG_ S405_0 : 277|32@1+ (1,0) [0|0] "u0" ECU

BO_ 662 M406: 2 ECU
 SG_ S406_0 : 7|13@0- (0.5,-40) [0|0] "u0" ECU

BO_ 663 M407: 8 ECU
 SG_ S407_0 : 25|15@1+ (1,0) [0|0] "u0" ECU

BO_ 664 M408: 16 ECU
 SG_ S408_0 : 68|44@1+ (1,0) [0|0] "u0" ECU

BO_ 665 M409: 4 ECU
 SG_ S409_0 : 7|32@0+ (1,0) [0|0] "u0" ECU

BO_ 2550137242 M410: 1 ECU
 SG_ S410_0 : 7|6@0- (1,0) [0|0] "u0" ECU

BO_ 667 M411: 2 ECU
 SG_ S411_0 : 4|10@1- (2,100.5) [0|0] "u0" ECU

BO_ 668 M412: 16 ECU
 SG_ S412_0 : 24|64@0+ (1,0) [0|0] "u0" ECU

BO_ 669 M413: 16 ECU
 SG_ S413_0 : 82|38@1+ (10,-0.25) [0|0] "u0" ECU

BO_ 670 M414: 1 ECU
 SG_ S414_0 : 4|4@0+ (0.5,0) [0|0] "u0" ECU

BO_ 2550137247 M415: 2 ECU
 SG_ S415_0 : 15|2@0- (2,-40) [0|0] "u0" ECU

BO_ 672 M416: 8 ECU
 SG_ S416_0 : 0|25@0+ (0.5,0) [0|0] "u0" ECU

BO_ 673 M417: 16 ECU
 SG_ S417_0 : 36|32@0+ (1,0) [0|0] "u0" ECU

BO_ 674 M418: 16 ECU
 SG_ S418_0 : 49|40@1+ (0.125,0) [0|0] "u0" ECU

BO_ 675 M419: 64 ECU
 SG_ S419_0 : 83|51@0- (1,0) [0|0] "u0" ECU

BO_ 1900 MIXED: 8 ECU
 SG_ Le16 : 0|16@1- (0.5,-40) [0|0] "degC" ECU
 SG_ Be12 : 19|12@0+ (1,0) [0|0] "" ECU
 SG_ Flag : 16|1@1+ (1,0) [0|0] "" ECU
 SG_ Be32 : 39|32@0- (0.001,0) [0|0] "V" ECU

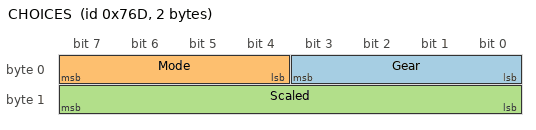
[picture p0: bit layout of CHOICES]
BO_ 1901 CHOICES: 2 ECU
 SG_ Gear : 0|4@1+ (1,0) [0|0] "" ECU
 SG_ Mode : 4|4@1- (1,0) [0|0] "" ECU
 SG_ Scaled : 8|8@1+ (0.5,0) [0|0] "" ECU

BO_ 2000 MUX: 8 ECU
 SG_ Sel M : 0|4@1+ (1,0) [0|0] "" ECU
 SG_ A m0 : 8|16@1- (0.1,0) [0|0] "a" ECU
 SG_ B m1 : 15|16@0+ (1,0) [0|0] "b" ECU
 SG_ Always : 56|8@1+ (1,0) [0|0] "" ECU

CM_ BO_ 256 "first line
BO_ 999 Fake: 8 ECU
 SG_ Bogus : 0|8@1+ (1,0) [0|0] \"x\" ECU
last";
VAL_ 1901 Gear 0 "Park" 1 "Reverse" 2 "Neutral" 3 "Drive" ;
VAL_ 1901 Mode -1 "Invalid" 0 "Off" 1 "Say \"on\"" ;
VAL_ 1901 Scaled 2 "Two raw" 255 "Top" ;
VAL_ EnvSwitch 0 "Off" 1 "On" ;
SIG_VALTYPE_ 2550136842 S10_0 : 1;
SIG_VALTYPE_ 275 S19_0 : 1;
SIG_VALTYPE_ 288 S32_0 : 1;
SIG_VALTYPE_ 2550136887 S55_0 : 1;
SIG_VALTYPE_ 312 S56_0 : 2;
SIG_VALTYPE_ 329 S73_0 : 1;
SIG_VALTYPE_ 2550136907 S75_0 : 1;
SIG_VALTYPE_ 347 S91_0 : 2;
SIG_VALTYPE_ 350 S94_0 : 1;
SIG_VALTYPE_ 357 S101_0 : 1;
SIG_VALTYPE_ 375 S119_0 : 1;
SIG_VALTYPE_ 383 S127_0 : 2;
SIG_VALTYPE_ 384 S128_0 : 1;
SIG_VALTYPE_ 2550136962 S130_0 : 1;
SIG_VALTYPE_ 433 S177_0 : 2;
SIG_VALTYPE_ 442 S186_0 : 2;
SIG_VALTYPE_ 458 S202_0 : 2;
SIG_VALTYPE_ 467 S211_0 : 1;
SIG_VALTYPE_ 483 S227_0 : 2;
SIG_VALTYPE_ 492 S236_0 : 2;
SIG_VALTYPE_ 2550137072 S240_0 : 2;
SIG_VALTYPE_ 510 S254_0 : 1;
SIG_VALTYPE_ 519 S263_0 : 1;
SIG_VALTYPE_ 2550137122 S290_0 : 2;
SIG_VALTYPE_ 548 S292_0 : 1;
SIG_VALTYPE_ 2550137137 S305_0 : 1;
SIG_VALTYPE_ 635 S379_0 : 1;
SIG_VALTYPE_ 2550137222 S390_0 : 1;
SIG_VALTYPE_ 652 S396_0 : 2;
SIG_VALTYPE_ 2550137237 S405_0 : 1;
SIG_VALTYPE_ 668 S412_0 : 2;
SIG_VALTYPE_ 673 S417_0 : 1;
